# NUC505_v1 register map
File version: 1.0
Registers are 32-bit, read-write, reset 0x0 unless marked. A register's access mark holds for its fields unless they carry their own. Offsets are from the block's base; [hi:lo] are bit positions.

## SCS — SCS Register Map
Base 0xE000E000
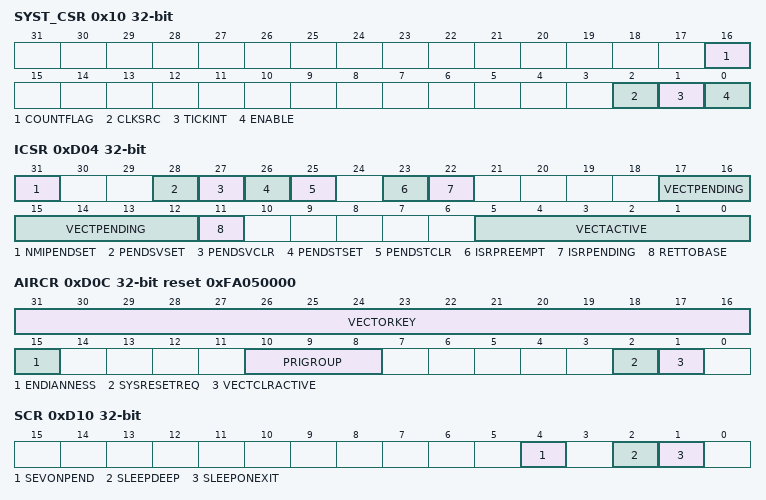
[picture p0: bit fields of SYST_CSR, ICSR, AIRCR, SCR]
0x10 SYST_CSR — SysTick Control and Status Register
  [16] COUNTFLAG — Returns 1 If Timer Counted to 0 Since Last Time this Register Was Read. COUNTFLAG is set by a count transition from 1 to 0. COUNTFLAG is cleared on read or by a write to the Current Value register.
  [2] CLKSRC — SysTick Counting Clock Source Select
    0=Clock source is (optional) external reference clock; 1=Core clock used for SysTick
  [1] TICKINT — SysTick Interrupt Enable Control
    0=Counting down to 0 does not cause the SysTick exception to be pended. Software can use COUNTFLAG to determine if a count to zero has occurred; 1=Counting down to 0 will cause the SysTick exception to be pended. Clearing the SysTickcurrent value register by a register write in software will not cause SysTick to be pended
  [0] ENABLE — SysTick Function Enable Control
    0=Counter Disabled; 1=Counter will operate in a multi-shot manner
0x14 SYST_RVR reset not defined — SysTick Reload Value Register
  [23:0] RELOAD — SysTick Reload Value. The value to load into the Current Value register when the counter reaches 0.
0x18 SYST_CVR reset not defined — SysTick Current Value Register
  [23:0] CURRENT — Current Counter Value. This is the value of the counter at the time it is sampled.The counter does not provide read-modify-write protection.The register is write-clear.A software write of any value will clear the register to 0.Unsupported bits RAZ (See SysTick reload value register).
0x100 NVIC_ISER0 — IRQ0 ~ IRQ31 Set-enable Control Register
  [31:0] SETENA — Interrupt Set Enable Control. The NVIC_ISER0 registers enable interrupts, and show which interrupts are enabled. Write Operation:
    0=No effect. Interrupt Disabled; 1=Interrupt Enabled
0x180 NVIC_ICER0 — IRQ0 ~ IRQ31 Clear-enable Control Register
  [31:0] CLRENA — Interrupt Clear Enable Control. The NVIC_ICER0 registers disable interrupts, and show which interrupts are enabled. Write Operation:
    0=No effect. Interrupt Disabled; 1=Interrupt Disabled. Interrupt Enabled
0x200 NVIC_ISPR0 — IRQ0 ~ IRQ31 Set-pending Control Register
  [31:0] SETPEND — Interrupt Set-pending. The NVIC_ISPR0 registers force interrupts into the pending state, and show which interrupts are pending. Write Operation:
    0=No effect. Interrupt is not pending; 1=Changes interrupt state to pending. Interrupt is pending
0x280 NVIC_ICPR0 — IRQ0 ~ IRQ31 Clear-pending Control Register
  [31:0] CLRPEND — Interrupt Clear-pending. The NVIC_ICPR0 registers remove the pending state from interrupts, and show which interrupts are pending. Write Operation:
    0=No effect. Interrupt is not pending; 1=Removes pending state an interrupt. Interrupt is pending
0x300 NVIC_IABR0 — IRQ0 ~ IRQ31 Active Bit Register
  [31:0] ACTIVE — Interrupt Active Flags. The NVIC_IABR0 registers indicate which interrupts are active.
    0=Interrupt is not active; 1=Interrupt is active
0xD04 ICSR — Interrupt Control and State Register
  [31] NMIPENDSET — NMI Set-pending Bit. Write Operation: Note: Because NMI is the highest-priority exception, normally the processor enters the NMI exception handler as soon as it detects a write of 1 to this bit. Entering the handler then clears this bit to 0. This means a read of this bit by the NMI exception handler returns 1 only if the NMI signal is reasserted while the processor is executing that handler.
    0=No effect. NMI exception is not pending; 1=Changes NMI exception state to pending. NMI exception is pending
  [28] PENDSVSET — PendSV Set-pending Bit. Write Operation: Note: Writing 1 to this bit is the only way to set the PendSV exception state to pending.
    0=No effect. PendSV exception is not pending; 1=Changes PendSV exception state to pending. PendSV exception is pending
  [27] PENDSVCLR — PendSV Clear-pending Bit. Write Operation: Note: This is a write only bit. To clear the PENDSV bit, you must "write 0 to PENDSVSET and write 1 to PENDSVRTC_CAL" at the same time.
    0=No effect; 1=Removes the pending state from the PendSV exception
  [26] PENDSTSET — SysTick Exception Set-pending Bit. Write Operation:
    0=No effect. SysTick exception is not pending; 1=Change SysTick exception state to pending. SysTick exception is pending
  [25] PENDSTCLR — SysTick Exception Clear-pending Bit. Write Operation: Note: This is a write only bit. To clear the PENDST bit, you must "write 0 to PENDSTSET and write 1 to PENDSTRTC_CAL" at the same time.
    0=No effect; 1=Removes the pending state from the SysTick exception
  [23] ISRPREEMPT ro — Interrupt Preempt Bit (Read Only). If set, a pending exception will be serviced on exit from the debug halt state.
  [22] ISRPENDING ro — Interrupt Pending Flag, Excluding NMI and Faults (Read Only)
    0=Interrupt not pending; 1=Interrupt pending
  [17:12] VECTPENDING — Number of the Highest Pended Exception. Indicates the exception number of the highest priority pending enabled exception. Note: The value indicated by this field includes the effect of the BASEPRI and FAULTMASK registers, but does not include any effect of the PRIMASK register.
    0=No pending exceptions
  [11] RETTOBASE — Preempted Active Exceptions Indicator. Indicate whether there are preempted active exceptions.
    0=There are preempted active exceptions to execute; 1=There are no active exceptions, or the currently-executing exception is the only active exception
  [5:0] VECTACTIVE — Number of the Current Active Exception
    0=Thread mode
0xD0C AIRCR reset 0xFA050000 — Application Interrupt and Reset Control Register
  [31:16] VECTORKEY — Register Access Key. When writing this register, this field should be 0x05FA; otherwise, the write action will be unpredictable. The VECTORKEY filed is used to prevent accidental write to this register from resetting the system or clearing of the exception status.
  [15] ENDIANNESS — Data Endianness
    0=Little-endian; 1=Big-endian
  [10:8] PRIGROUP — Interrupt Priority Grouping. This field determines the Split of Group priority from subpriority,
  [2] SYSRESETREQ — System Reset Request. Writing this bit to 1 will cause a reset signal to be asserted to the chip and indicate a reset is requested. Note: This bit is write only and self-cleared as part of the reset sequence.
  [1] VECTCLRACTIVE — Exception Active Status Clear Bit. Setting this bit to 1 will clear all active state information for fixed and configurable exceptions. Note1: This bit is write only and can only be written when the core is halted. Note2: It is the debugger's responsibility to re-initialize the stack.
0xD10 SCR — System Control Register
  [4] SEVONPEND — Send Event on Pending. When an event or interrupt enters pending state, the event signal wakes up the processor from WFE. If the processor is not waiting for an event, the event is registered and affects the next WFE. The processor also wakes up on execution of an SEV instruction or an external event.
    0=Only enabled interrupts or events can wake up the processor, while disabled interrupts are excluded; 1=Enabled events and all interrupts, including disabled interrupts, can wake up the processor
  [2] SLEEPDEEP — Processor Deep Sleep and Sleep Mode Selection. Control whether the processor uses Idle mode or Power-down mode as its low power operation.
    0=Idle mode; 1=Power-down mode
  [1] SLEEPONEXIT — Sleep-on-exit Enable Control. This bit indicates Sleep-On-Exit when returning from handler mode to thread mode. Setting this bit to 1 will enable an interrupt driven application to avoid returning to an empty main application.
    0=Do not enter idle mode when returning to Thread mode; 1=Enter Idle mode, or Power-down mode, on return from an ISR to Thread mode
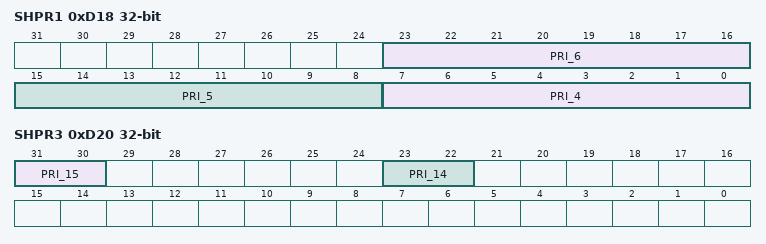
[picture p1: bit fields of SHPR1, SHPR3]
0xD18 SHPR1 — System Handler Priority Register 1
  [23:16] PRI_6 — Priority of System Handler 6 - UsageFault "0" denotes the highest priority and "3" denotes the lowest priority.
  [15:8] PRI_5 — Priority of System Handler 5 - BusFault "0" denotes the highest priority and "3" denotes the lowest priority.
  [7:0] PRI_4 — Priority of System Handler 4 - MemManage "0" denotes the highest priority and "3" denotes the lowest priority.
0xD1C SHPR2 — System Handler Priority Register 2
  [31:30] PRI_11 — Priority of System Handler 11 - SVCall "0" denotes the highest priority and "3" denotes the lowest priority.
0xD20 SHPR3 — System Handler Priority Register 3
  [31:30] PRI_15 — Priority of System Handler 15 - SysTick "0" denotes the highest priority and "3" denotes the lowest priority.
  [23:22] PRI_14 — Priority of System Handler 14 - PendSV "0" denotes the highest priority and "3" denotes the lowest priority.
0xF00 NVIC_STIR wo — Software Trigger Interrupt Registers
  [8:0] INTID — Write to the STIR to Generate an Interrupt From Software. When the USERSETMPEND bit in the SCR is set to 1, unprivileged software can access the STIR. Interrupt ID of the interrupt to trigger, in the range 0-47. For example, a value of 0x03 specifies interrupt IRQ3.
